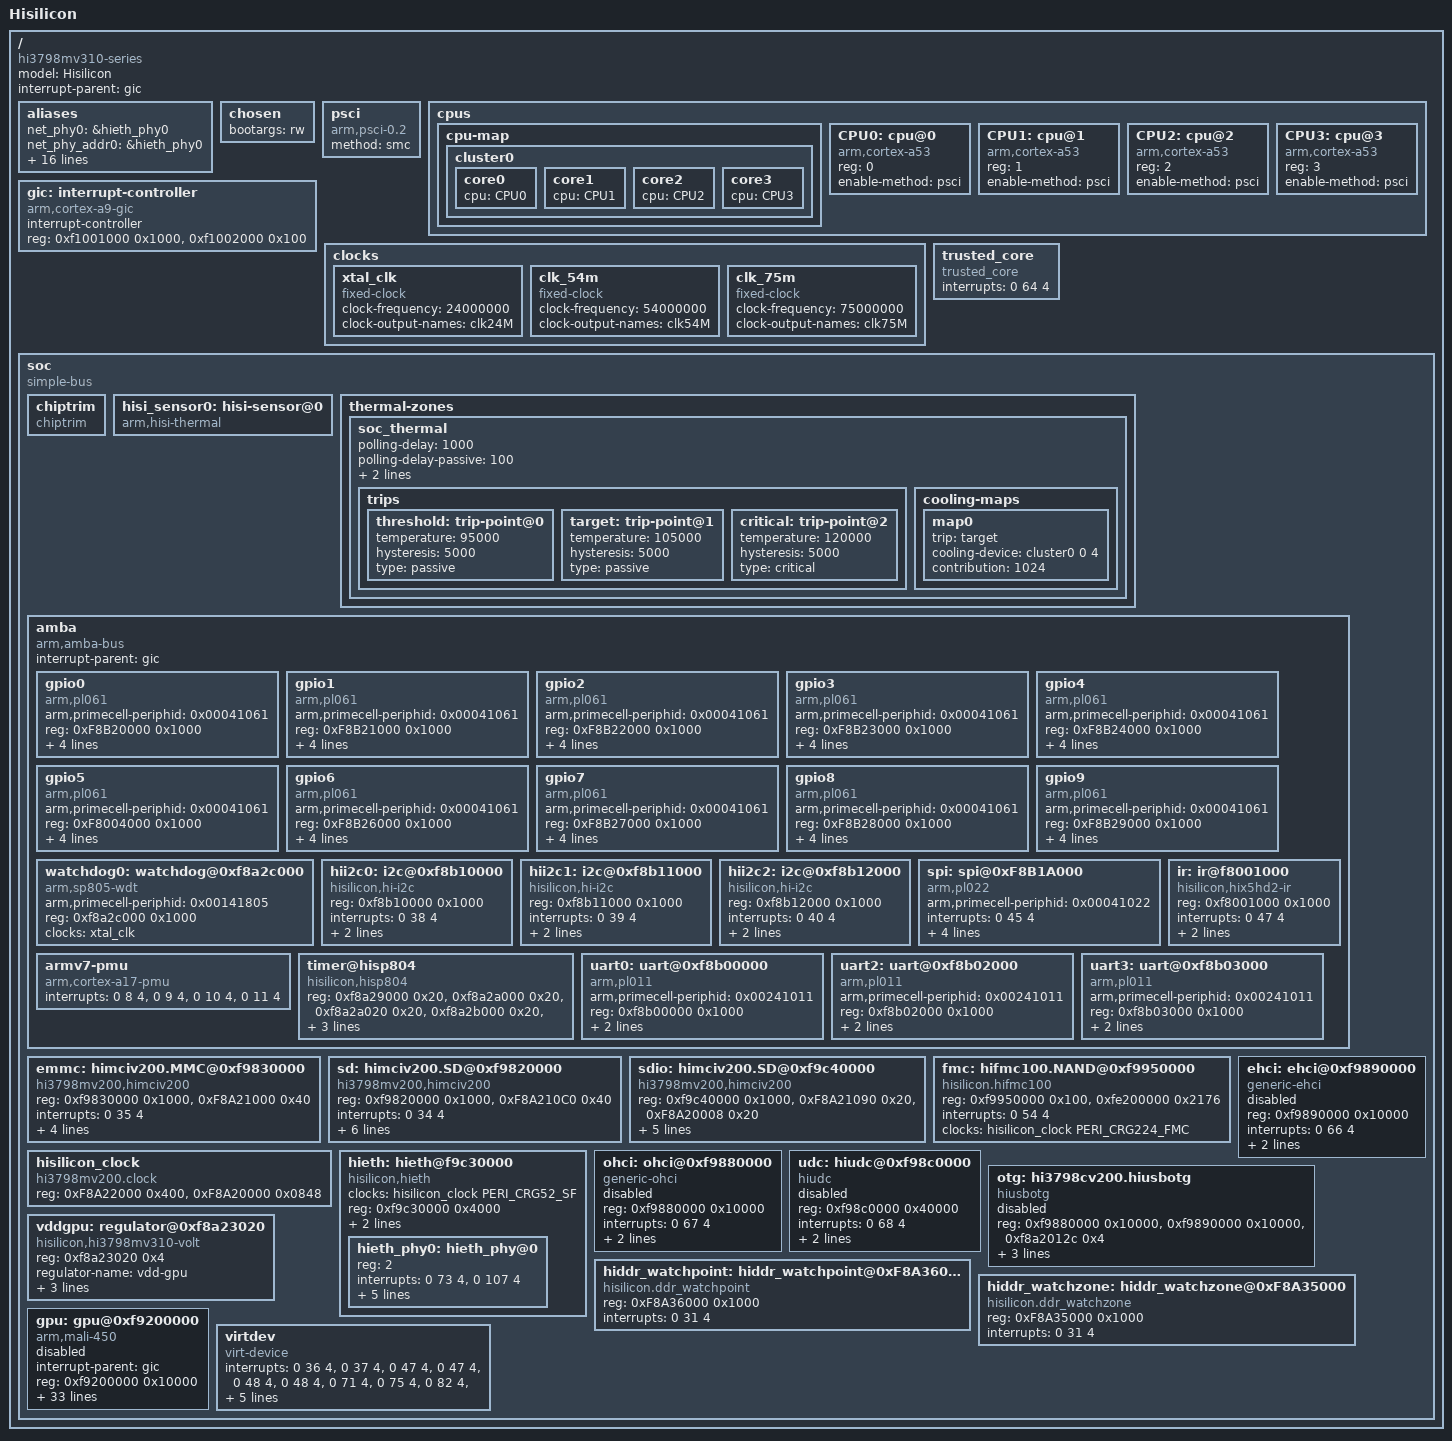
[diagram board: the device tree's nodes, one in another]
/dts-v1/;

#include <dt-bindings/clock/hi3798mv310-clock.h>

/ {
	model = "Hisilicon";
	compatible = "hi3798mv310-series";
	#address-cells = <1>;
	#size-cells = <1>;
	interrupt-parent = <&gic>;

	aliases {
		net_phy0 = &hieth_phy0;

		net_phy_addr0 = &hieth_phy0;
		emmc = &emmc;
		sd   = &sd;
		sdio = &sdio;
		ohci0= &ohci;
		ehci0= &ehci;
		uart0= &uart0;
		uart2= &uart2;
		uart3= &uart3;
		fmc  = &fmc;
		udc  = &udc;
		otg  = &otg;
		i2c0=&hii2c0;
		i2c1=&hii2c1;
		i2c2=&hii2c2;
		spi0=&spi;
		chiptrim=&chiptrim;
	};

	chosen {
		bootargs = "rw";
	};

	psci {
		compatible = "arm,psci-0.2";
		method = "smc";
	};
	cpus {
			#address-cells = <1>;
			#size-cells = <0>;

			/* cooling options */
			#cooling-cells = <2>; /* min followed by max */

			cpu-map {
				cluster0: cluster0 {
					core0 {
						cpu = <&CPU0>;
					};
					core1 {
						cpu = <&CPU1>;
					};
					core2 {
						cpu = <&CPU2>;
					};
					core3 {
						cpu = <&CPU3>;
					};
				};
			};

			CPU0: cpu@0 {
				compatible = "arm,cortex-a53";
				device_type = "cpu";
				reg = <0>;
				enable-method = "psci";
			};
			CPU1: cpu@1 {
				compatible = "arm,cortex-a53";
				device_type = "cpu";
				reg = <1>;
				enable-method = "psci";
			};
			CPU2: cpu@2 {
				compatible = "arm,cortex-a53";
				device_type = "cpu";
				reg = <2>;
				enable-method = "psci";
			};
			CPU3: cpu@3 {
				compatible = "arm,cortex-a53";
				device_type = "cpu";
				reg = <3>;
				enable-method = "psci";
			};

	}; /* cpus */

	gic: interrupt-controller {
		compatible = "arm,cortex-a9-gic";
		#interrupt-cells = <3>;
		#address-cells = <0>;
		interrupt-controller;
		reg = <0xf1001000 0x1000>,
		      <0xf1002000 0x100>;
	};

	clocks {
		xtal_clk: xtal_clk {
			compatible = "fixed-clock";
			#clock-cells = <0>;
			clock-frequency = <24000000>;
			clock-output-names = "clk24M";
		};

		clk_54m: clk_54m{
			compatible = "fixed-clock";
			#clock-cells = <0>;
			clock-frequency = <54000000>;
			clock-output-names = "clk54M";
		};

		clk_75m: clk_75m{
			compatible = "fixed-clock";
			#clock-cells = <0>;
			clock-frequency = <75000000>;
			clock-output-names = "clk75M";
		};
	};

	trusted_core {
		compatible = "trusted_core";
		interrupts = <0 64 4>;
	};


	soc {
		#address-cells = <1>;
		#size-cells = <1>;
		compatible = "simple-bus";
		device_type = "soc";
		ranges = <0x0 0x0 0xffffffff>;

		chiptrim: chiptrim {
			compatible = "chiptrim";
		};

		hisi_sensor0: hisi-sensor@0 {
			compatible = "arm,hisi-thermal";
			#thermal-sensor-cells = <1>;
		};

		thermal-zones {
			soc_thermal {
				polling-delay = <1000>;
				polling-delay-passive = <100>;
				sustainable-power = <2500>;

				thermal-sensors = <&hisi_sensor0 0>;

				trips {
					threshold: trip-point@0 {
						temperature = <95000>;
						hysteresis = <5000>;
						type = "passive";
					};
					target: trip-point@1 {
						temperature = <105000>;
						hysteresis = <5000>;
						type = "passive";
					};
					critical: trip-point@2 {
						temperature = <120000>;
						hysteresis = <5000>;
						type = "critical";
					};
				};

				cooling-maps {
					map0 {
					     trip = <&target>;
					     cooling-device = <&cluster0 0 4>;
					     contribution = <1024>;
					};
				};
			};
		};

		amba {
			compatible = "arm,amba-bus";
			#address-cells = <1>;
			#size-cells = <1>;
			interrupt-parent = <&gic>;
			ranges;

			gpio0: gpio0 {
				compatible = "arm,pl061", "arm,primecell";
				arm,primecell-periphid = <0x00041061>;
				reg = <0xF8B20000 0x1000>;
				interrupts = <0 108 0x4>;
				gpio-controller;
				#gpio-cells = <2>;
				interrupt-controller;
				#interrupt-cells = <2>;
				clocks = <&xtal_clk>;
				clock-names = "apb_pclk";
			};

			gpio1: gpio1 {
				compatible = "arm,pl061", "arm,primecell";
				arm,primecell-periphid = <0x00041061>;
				reg = <0xF8B21000 0x1000>;
				interrupts = <0 109 4>;
				gpio-controller;
				#gpio-cells = <2>;
				interrupt-controller;
				#interrupt-cells = <2>;
				clocks = <&xtal_clk>;
				clock-names = "apb_pclk";
			};

			gpio2: gpio2 {
				compatible = "arm,pl061", "arm,primecell";
				arm,primecell-periphid = <0x00041061>;
				reg = <0xF8B22000 0x1000>;
				interrupts = <0 110 4>;
				gpio-controller;
				#gpio-cells = <2>;
				interrupt-controller;
				#interrupt-cells = <2>;
				clocks = <&xtal_clk>;
				clock-names = "apb_pclk";
			};

			gpio3: gpio3 {
				compatible = "arm,pl061", "arm,primecell";
				arm,primecell-periphid = <0x00041061>;
				reg = <0xF8B23000 0x1000>;
				interrupts = <0 111 4>;
				gpio-controller;
				#gpio-cells = <2>;
				interrupt-controller;
				#interrupt-cells = <2>;
				clocks = <&xtal_clk>;
				clock-names = "apb_pclk";
			};

			gpio4: gpio4 {
				compatible = "arm,pl061", "arm,primecell";
				arm,primecell-periphid = <0x00041061>;
				reg = <0xF8B24000 0x1000>;
				interrupts = <0 112 4>;
				gpio-controller;
				#gpio-cells = <2>;
				interrupt-controller;
				#interrupt-cells = <2>;
				clocks = <&xtal_clk>;
				clock-names = "apb_pclk";
			};

			gpio5: gpio5 {
				compatible = "arm,pl061", "arm,primecell";
				arm,primecell-periphid = <0x00041061>;
				reg = <0xF8004000 0x1000>;
				interrupts = <0 113 0>;
				gpio-controller;
				#gpio-cells = <2>;
				interrupt-controller;
				#interrupt-cells = <2>;
				clocks = <&xtal_clk>;
				clock-names = "apb_pclk";
			};

			gpio6: gpio6 {
				compatible = "arm,pl061", "arm,primecell";
				arm,primecell-periphid = <0x00041061>;
				reg = <0xF8B26000 0x1000>;
				interrupts = <0 114 4>;
				gpio-controller;
				#gpio-cells = <2>;
				interrupt-controller;
				#interrupt-cells = <2>;
				clocks = <&xtal_clk>;
				clock-names = "apb_pclk";
			};

			gpio7: gpio7 {
				compatible = "arm,pl061", "arm,primecell";
				arm,primecell-periphid = <0x00041061>;
				reg = <0xF8B27000 0x1000>;
				interrupts = <0 115 4>;
				gpio-controller;
				#gpio-cells = <2>;
				interrupt-controller;
				#interrupt-cells = <2>;
				clocks = <&xtal_clk>;
				clock-names = "apb_pclk";
			};

			gpio8: gpio8 {
				compatible = "arm,pl061", "arm,primecell";
				arm,primecell-periphid = <0x00041061>;
				reg = <0xF8B28000 0x1000>;
				interrupts = <0 116 4>;
				gpio-controller;
				#gpio-cells = <2>;
				interrupt-controller;
				#interrupt-cells = <2>;
				clocks = <&xtal_clk>;
				clock-names = "apb_pclk";
			};

			gpio9: gpio9 {
				compatible = "arm,pl061", "arm,primecell";
				arm,primecell-periphid = <0x00041061>;
				reg = <0xF8B29000 0x1000>;
				interrupts = <0 117 4>;
				gpio-controller;
				#gpio-cells = <2>;
				interrupt-controller;
				#interrupt-cells = <2>;
				clocks = <&xtal_clk>;
				clock-names = "apb_pclk";
			};

			watchdog0: watchdog@0xf8a2c000 {
				compatible = "arm,sp805-wdt", "arm,primecell";
				arm,primecell-periphid = <0x00141805>;
				reg = <0xf8a2c000 0x1000>;
				clocks = <&xtal_clk>;
				clock-names = "apb_pclk";
			};

			hii2c0:i2c@0xf8b10000 {
				compatible = "hisilicon,hi-i2c";
				reg = <0xf8b10000 0x1000>;
				interrupts = <0 38 4>;
				clock-frequency = <400000>;
				clocks = <&hisilicon_clock HII2C_I2C0_CLK>;
				clock-names = "apb_pclk";
				#address-cells = <1>;
				#size-cells = <0>;
			};

			hii2c1:i2c@0xf8b11000 {
				compatible = "hisilicon,hi-i2c";
				reg = <0xf8b11000 0x1000>;
				interrupts = <0 39 4>;
				clock-frequency = <400000>;
				clocks = <&hisilicon_clock HII2C_I2C1_CLK>;
				clock-names = "apb_pclk";
				#address-cells = <1>;
				#size-cells = <0>;
			};

			hii2c2:i2c@0xf8b12000 {
				compatible = "hisilicon,hi-i2c";
				reg = <0xf8b12000 0x1000>;
				interrupts = <0 40 4>;
				clock-frequency = <400000>;
				clocks = <&hisilicon_clock HII2C_I2C2_CLK>;
				clock-names = "apb_pclk";
				#address-cells = <1>;
				#size-cells = <0>;
			};

			spi:spi@0xF8B1A000 {
				compatible = "arm,pl022", "arm,primecell";
				arm,primecell-periphid = <0x00041022>;
				interrupts = <0 45 4>;
				reg = <0xF8B1A000 0x1000>;
				num-cs = <2>;
				#address-cells = <1>;
				#size-cells = <0>;
				clocks = <&hisilicon_clock PERI_CRG28_SSP>;
				clock-names = "apb_pclk";
				pl022,rt;

				/* userspace spi interface
				 * parse by of_register_spi_devices function
				 */
				/*spidev@0 {
				*	compatible = "rohm,dh2228fv";
				*	reg = <1>;
				* 	spi-max-frequency = <16000000>;
				* };
				*/
			};

			/*
			 *spi_gpio: spi-gpio {
			 *	compatible = "spi-gpio";
			 *	#address-cells = <1>;
			 *	#size-cells = <0>;
			 *	gpio-sck = <&gpio1 1 0>;
			 *	gpio-miso = <&gpio1 3 0>;
			 *	gpio-mosi = <&gpio1 2 0>;
			 *	num-chipselects = <1>;
			 *	cs-gpios = <&gpio1 4 1>;
			 *};
			 */

			ir: ir@f8001000 {
				compatible = "hisilicon,hix5hd2-ir";
				reg = <0xf8001000 0x1000>;
				interrupts = <0 47 4>;
				clocks = <&hisilicon_clock HIIR_CLK>;
				linux,rc-map-name = "rc-hisi";
			};

			armv7-pmu {
				compatible = "arm,cortex-a17-pmu";
				interrupts = <0 8 4>,
					     <0 9 4>,
					     <0 10 4>,
					     <0 11 4>;
			};
#if 0
			arm-timer {
				compatible = "arm,armv7-timer";
				interrupts = <1 13 0xf04>,
				             <1 14 0xf04>;
				clock-frequency = <24000000>;
			};
#endif
			timer@hisp804 {
				compatible = "hisilicon,hisp804";
				reg = <0xf8a29000 0x20>, /* clocksource */
				      <0xf8a2a000 0x20>, /* local timer for each cpu */
				      <0xf8a2a020 0x20>,
				      <0xf8a2b000 0x20>,
				      <0xf8a2b020 0x20>;
				interrupts = <0 26 4>, /* irq of local timer */
					     <0 59 4>,
					     <0 27 4>,
					     <0 60 4>;
				clocks = <&xtal_clk>;
				clock-names = "apb_pclk";
			};

			uart0: uart@0xf8b00000 {
				compatible = "arm,pl011", "arm,primecell";
				arm,primecell-periphid = <0x00241011>;
				reg = <0xf8b00000 0x1000>;
				interrupts = <0 49 4>;
				clocks = <&clk_75m>;
				clock-names = "apb_pclk";
				status = "okay";
			};

			uart2: uart@0xf8b02000 {
				compatible = "arm,pl011", "arm,primecell";
				arm,primecell-periphid = <0x00241011>;
				reg = <0xf8b02000 0x1000>;
				interrupts = <0 51 4>;
				clocks = <&clk_75m>;
				clock-names = "apb_pclk";
				status = "okay";
			};

			uart3: uart@0xf8b03000 {
				compatible = "arm,pl011", "arm,primecell";
				arm,primecell-periphid = <0x00241011>;
				reg = <0xf8b03000 0x1000>;
				interrupts = <0 52 4>;
				clocks = <&clk_75m>;
				clock-names = "apb_pclk";
				status = "okay";
			};

		};

		emmc: himciv200.MMC@0xf9830000 {
			compatible = "hi3798mv200,himciv200";
			reg = <0xf9830000 0x1000>,<0xF8A21000 0x40>;
			interrupts = <0 35 4>;

			clocks = <&hisilicon_clock PERI_CRG40_SDIO1>;
			clock-names = "clk";

			caps = <0xc0000847>;
			caps2 = <0x0>;
			max-frequency = <50000000>;
			status = "okay";
		};

		sd:himciv200.SD@0xf9820000 {
			compatible = "hi3798mv200,himciv200";
			reg = <0xf9820000 0x1000>,<0xF8A210C0 0x40>;
			interrupts = <0 34 4>;

			clocks = <&hisilicon_clock PERI_CRG39_SDIO0>;
			clock-names = "clk";

			ldo-addr  = <0xf8a2011c>;
			ldo-shift = <0>;

			caps = <0x8007000f>;
			caps2 = <0x4000>;
			max-frequency = <50000000>;
			status = "okay";
		};

		sdio:himciv200.SD@0xf9c40000 {
			compatible = "hi3798mv200,himciv200";
			reg = <0xf9c40000 0x1000>,<0xF8A21090 0x20>,<0xF8A20008 0x20>;
			interrupts = <0 86 4>;

			clocks = <&hisilicon_clock PERI_CRG163_SDIO2>;
			clock-names = "clk";

			caps = <0x8007000f>;
			caps2 = <0x4000>;
			max-frequency = <50000000>;
			status = "okay";
		};

		fmc:hifmc100.NAND@0xf9950000 {
			compatible = "hisilicon.hifmc100";
			reg = <0xf9950000 0x100>, <0xfe200000 0x2176>;
			interrupts = <0 54 4>;

			clocks = <&hisilicon_clock PERI_CRG224_FMC>;
			clock-names = "clk";
			status = "okay";
		};

		hisilicon_clock: hisilicon_clock {
			compatible = "hi3798mv200.clock","hisilicon,clock-reset";
			reg = <0xF8A22000 0x400>, <0xF8A20000 0x0848>;
			#clock-cells = <1>;
			#reset-cells = <2>;
		};
		hieth: hieth@f9c30000 {
			compatible = "hisilicon,hieth";
			clocks = <&hisilicon_clock PERI_CRG52_SF>;
			clock-names = "clk";
			reg = <0xf9c30000 0x4000>;
			interrupts = <0 72 4>;
			phy-handle = <&hieth_phy0>;
			#address-cells = <1>;
			#size-cells = <0>;
			status = "okay";

			hieth_phy0: hieth_phy@0 {
				reg = <2>;
				interrupts = <0 73 4>, <0 107 4>;
				mac-address = [00 00 00 00 00 00];
				phy-mode = "mii";
				phy-gpio-base = <0>;
				phy-gpio-bit = <0>;
				internal-phy;
			};
		};


		ehci:ehci@0xf9890000 {
			compatible = "generic-ehci";
			reg = <0xf9890000 0x10000>;
			interrupts = <0 66 4>;

			clocks = <&hisilicon_clock PERI_CRG46_USB2CTRL>;
			clock-names = "clk";
			#status = "okay";
            		status = "disabled";
		};

		ohci:ohci@0xf9880000 {
			compatible = "generic-ohci";
			reg = <0xf9880000 0x10000>;
			interrupts = <0 67 4>;

			clocks = <&hisilicon_clock PERI_CRG46_USB2CTRL>;
			clock-names = "clk";
			#status = "okay";
            		status = "disabled";
		};

		udc:hiudc@0xf98c0000 {
			compatible = "hiudc";
			reg = <0xf98c0000 0x40000>;
			interrupts = <0 68 4>;

			clocks = <&hisilicon_clock PERI_CRG46_USB2CTRL>;
			clock-names = "clk";
			#status = "okay";
            		status = "disabled";
		};

		otg:hi3798cv200.hiusbotg {
			compatible = "hiusbotg";
			reg = <0xf9880000 0x10000>,<0xf9890000 0x10000>,<0xf8a2012c 0x4>;
			host_time = <1500 4>;
			device_time = <1000 4>;
			#status = "okay";
            		status = "disabled";
		};


		hiddr_watchpoint: hiddr_watchpoint@0xF8A36000 {
			compatible = "hisilicon.ddr_watchpoint";
			reg = <0xF8A36000 0x1000>;
			interrupts = <0 31 4>;
		};
		hiddr_watchzone: hiddr_watchzone@0xF8A35000 {
			compatible = "hisilicon.ddr_watchzone";
			reg = <0xF8A35000 0x1000>;
			interrupts = <0 31 4>;
		};

		vddgpu: regulator@0xf8a23020 {
			compatible = "hisilicon,hi3798mv310-volt";
			reg = <0xf8a23020 0x4>;
			reg-names = "Hisilicon GPU Regulator";
			regulator-name = "vdd-gpu";
			regulator-min-microvolt = <700000>;
			regulator-max-microvolt = <1250000>;
			regulator-always-on;
			status = "okay";
		};

		gpu:gpu@0xf9200000 {
			compatible = "arm,mali-450", "arm,mali-utgard";
			interrupt-parent = <&gic>;
			reg = <0xf9200000 0x10000>;
			interrupts = <0 94 4>, <0 94 4>, <0 94 4>, <0 94 4>, <0 94 4>, <0 94 4>, <0 94 4>, <0 94 4>;
			interrupt-names = "IRQGP", "IRQGPMMU", "IRQPP0", "IRQPPMMU0", "IRQPP1", "IRQPPMMU1", "IRQPMU", "IRQPP";
			pmu_domain_config = <0x1 0x2 0x2 0x0 0x0 0x0 0x0 0x0 0x0 0x1 0x2 0x0>;
			pmu_switch_delay = <0x1ff>;
			#cooling-cells = <2>;
			clocks = <&hisilicon_clock PERI_CRG73_GPU_LP>;
			clock-names = "clk_mali";
			mali-supply = <&vddgpu>;

			default-frequency = <600000000>;
			max-utilization   = <60>;
			min-utilization   = <30>;
			max-frequency     = <800000000>;
			min-frequency     = <200000000>;

			operating-points-tt = <
				200000000 870000
				300000000 870000
				400000000 870000
				500000000 870000
				600000000 870000
				675000000 900000
				750000000 910000
				800000000 930000>;
			operating-points-ss = <
				200000000 910000
				300000000 910000
				400000000 910000
				500000000 910000
				600000000 910000
				675000000 910000
				750000000 940000
				800000000 960000>;
			operating-points-ff = <
				200000000 830000
				300000000 830000
				400000000 830000
				500000000 830000
				600000000 830000
				675000000 850000
				750000000 890000
				800000000 900000>;

			operating-points-ff-98mv300 = <
				200000000 840000
				300000000 840000
				400000000 840000
				500000000 840000
				540000000 840000
				600000000 840000
				675000000 850000
				860000000 990000>;

			operating-points-tt-98mv300 = <
				200000000 880000
				300000000 880000
				400000000 880000
				500000000 880000
				540000000 880000
				600000000 880000
				675000000 900000
				860000000 990000>;

			operating-points-ss-98mv300 = <
				200000000 910000
				300000000 910000
				400000000 910000
				500000000 910000
				540000000 910000
				600000000 910000
				675000000 950000
				860000000 990000>;

			operating-points-tt-youtube = <
				200000000 870000
				300000000 870000
				400000000 870000
				500000000 870000
				600000000 870000
				675000000 900000
				800000000 930000>;
			operating-points-ss-youtube = <
				200000000 910000
				300000000 910000
				400000000 910000
				500000000 910000
				600000000 910000
				675000000 910000
				800000000 960000>;
			operating-points-ff-youtube = <
				200000000 830000
				300000000 830000
				400000000 830000
				500000000 830000
				600000000 830000
				675000000 850000
				800000000 900000>;

			cooling-min-state = <0>;
			cooling-max-state = <7>;
			#status = "okay";
            		status = "disabled";

		};



		virtdev {
			compatible = "virt-device";
			interrupts = <0 36 4>,  /* "sci0"          */
						 <0 37 4>,  /* "sci1"          */
						 <0 47 4>,  /* "ir_std"        */
						 <0 47 4>,  /* "ir_s2"         */
						 <0 48 4>,  /* "keyled_ct1642" */
						 <0 48 4>,  /* "keyled_std"    */
						 <0 71 4>,  /* "gsf0"          */
						 <0 75 4>,  /* "multicipher"   */
						 <0 82 4>,  /* "dmx"           */
						 <0 84 4>,  /* "aiao"          */
						 <0 88 4>,  /* "hdmi"          */
						 <0 90 4>,  /* "vdp"           */
						 <0 91 4>,  /* "tde"           */
						 <0 91 4>,  /* "gfx2d"         */
						 <0 93 4>,  /* "vpss0"         */
						 <0 94 4>,  /* "gpu"           */
						 <0 95 4>,  /* "vdec_vdh"      */
						 <0 96 4>,  /* "png"           */
						 <0 97 4>,  /* "jpeg"          */
						 <0 101 4>, /* "venc"          */
						 <0 102 4>, /* "jpge"          */
						 <0 104 4>, /* "vdec_scd"      */
						 <0 105 4>, /* "vdec_vdh_safe" */
						 <0 106 4>, /* "vdec_scd_safe" */
						 <0 126 4>, /* "cipher"        */
						 <0 146 4>, /* "SecInvokeirq"  */
						 <0 147 4>, /* "hdmi_cec"      */
						 <0 148 4>, /* "mmu_vdh_safe"  */
						 <0 149 4>, /* "mmu_vdh"       */
						 <0 150 4>, /* "pastc"         */
						 <0 157 4>; /* "sm2"         */
			interrupt-names = /* 36  */ "sci0",
							  /* 37  */ "sci1",
							  /* 47  */ "ir_std",
							  /* 47  */ "ir_s2",
							  /* 48  */ "keyled_ct1642",
							  /* 48  */ "keyled_std",
							  /* 71  */ "gsf0",
							  /* 75  */ "multicipher",
							  /* 82  */ "dmx",
							  /* 84  */ "aiao",
							  /* 88  */ "hdmi",
							  /* 90  */ "vdp",
							  /* 91  */ "tde",
							  /* 91  */ "gfx2d",
							  /* 93  */ "vpss0",
							  /* 94  */ "gpu",
							  /* 95  */ "vdec_vdh",
							  /* 96  */ "png",
							  /* 97  */ "jpeg",
							  /* 101 */ "venc",
							  /* 102 */ "jpge",
							  /* 104 */ "vdec_scd",
							  /* 105 */ "vdec_vdh_safe",
							  /* 106 */ "vdec_scd_safe",
							  /* 126 */ "cipher",
							  /* 146 */ "SecInvokeirq",
							  /* 147 */ "hdmi_cec",
							  /* 148 */ "mmu_vdh_safe",
							  /* 149 */ "mmu_vdh",
							  /* 150 */ "pastc",
							  /* 157 */ "sm2";
		};
	};
};
